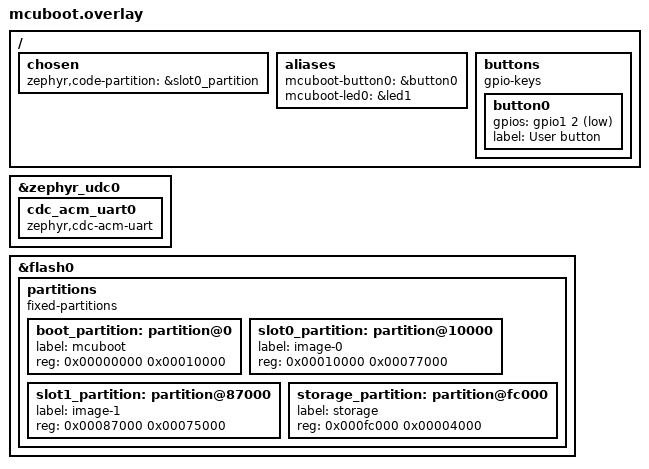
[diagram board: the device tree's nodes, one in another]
/{
	chosen{
		zephyr,code-partition = &slot0_partition;
	};

	aliases {
		mcuboot-button0 = &button0;
		mcuboot-led0 = &led1;
	};

	buttons {
		compatible = "gpio-keys";
		button0: button0 {
			// Use pin 2 on GPIO controller 1
			gpios = <&gpio1 2 (GPIO_PULL_UP | GPIO_ACTIVE_LOW)>;
			label = "User button";
		};
	};
};

&zephyr_udc0 {
	cdc_acm_uart0: cdc_acm_uart0 {
		compatible = "zephyr,cdc-acm-uart";
	};
};

&flash0 {
	/delete-node/ partitions;

	partitions {
		compatible = "fixed-partitions";
		#address-cells = <1>;
		#size-cells = <1>;

		boot_partition: partition@0 {
			label = "mcuboot";
			reg = <0x00000000 0x00010000>;
		};

		slot0_partition: partition@10000 {
			label = "image-0";
			reg = <0x00010000 0x00077000>;
		};

		slot1_partition: partition@87000 {
			label = "image-1";
			reg = <0x00087000 0x00075000>;
		};

		/*
		 * The flash starting at 0x000f8000 and ending at
		 * 0x000fffff is reserved for use by the application.
		 */

		/*
		 * Storage partition will be used by FCB/LittleFS/NVS
		 * if enabled.
		 */
		storage_partition: partition@fc000 {
			label = "storage";
			reg = <0x000fc000 0x00004000>;
		};
	};
};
